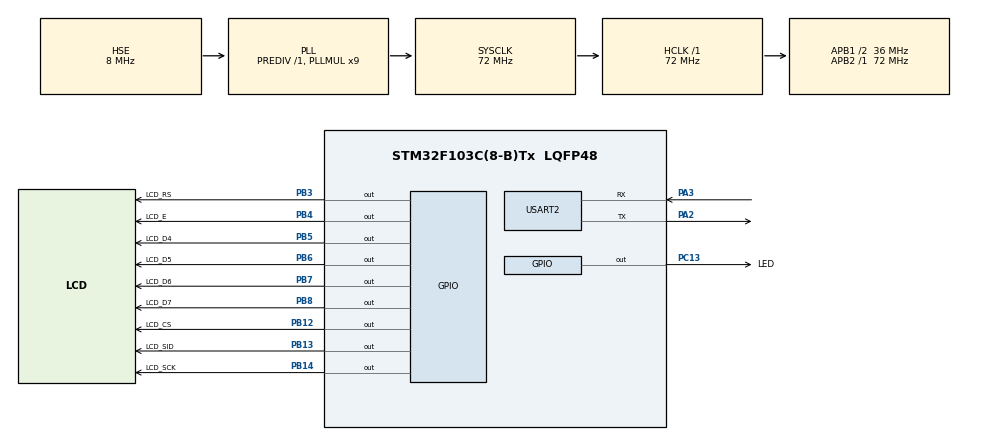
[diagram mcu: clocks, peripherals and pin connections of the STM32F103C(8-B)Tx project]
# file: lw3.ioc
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Dma.Request0=USART2_TX
Dma.Request1=USART2_RX
Dma.USART2_RX.1.Direction=DMA_PERIPH_TO_MEMORY
Dma.USART2_RX.1.Instance=DMA1_Channel6
Dma.USART2_RX.1.MemDataAlignment=DMA_MDATAALIGN_BYTE
Dma.USART2_RX.1.MemInc=DMA_MINC_ENABLE
Dma.USART2_RX.1.Mode=DMA_NORMAL
Dma.USART2_RX.1.PeriphDataAlignment=DMA_PDATAALIGN_BYTE
Dma.USART2_RX.1.PeriphInc=DMA_PINC_DISABLE
Dma.USART2_RX.1.Priority=DMA_PRIORITY_LOW
Dma.USART2_TX.0.Direction=DMA_MEMORY_TO_PERIPH
Dma.USART2_TX.0.Instance=DMA1_Channel7
Dma.USART2_TX.0.MemDataAlignment=DMA_MDATAALIGN_BYTE
Dma.USART2_TX.0.MemInc=DMA_MINC_ENABLE
Dma.USART2_TX.0.Mode=DMA_NORMAL
Dma.USART2_TX.0.PeriphDataAlignment=DMA_PDATAALIGN_BYTE
Dma.USART2_TX.0.PeriphInc=DMA_PINC_DISABLE
Dma.USART2_TX.0.Priority=DMA_PRIORITY_LOW
Mcu.Family=STM32F1
Mcu.Name=STM32F103C(8-B)Tx
Mcu.Package=LQFP48
NVIC.DMA1_Channel6_IRQn=true\:0\:0\:false\:false\:true\:false\:true\:true
NVIC.DMA1_Channel7_IRQn=true\:0\:0\:false\:false\:true\:false\:true\:true
NVIC.PriorityGroup=NVIC_PRIORITYGROUP_4
NVIC.USART2_IRQn=true\:0\:0\:false\:false\:true\:true\:true\:true
PA13.Mode=Serial_Wire
PA13.Signal=SYS_JTMS-SWDIO
PA14.Mode=Serial_Wire
PA14.Signal=SYS_JTCK-SWCLK
PA2.Mode=Asynchronous
PA2.Signal=USART2_TX
PA3.Mode=Asynchronous
PA3.Signal=USART2_RX
PB12.GPIO_Label=LCD_CS
PB12.Signal=GPIO_Output
PB13.GPIO_Label=LCD_SID
PB13.Signal=GPIO_Output
PB14.GPIO_Label=LCD_SCK
PB14.Signal=GPIO_Output
PB3.GPIO_Label=LCD_RS
PB3.Signal=GPIO_Output
PB4.GPIO_Label=LCD_E
PB4.Signal=GPIO_Output
PB5.GPIO_Label=LCD_D4
PB5.Signal=GPIO_Output
PB6.GPIO_Label=LCD_D5
PB6.Signal=GPIO_Output
PB7.GPIO_Label=LCD_D6
PB7.Signal=GPIO_Output
PB8.GPIO_Label=LCD_D7
PB8.Signal=GPIO_Output
PC13-TAMPER-RTC.GPIO_Label=LED
PC13-TAMPER-RTC.Signal=GPIO_Output
PD0-OSC_IN.Mode=HSE-External-Oscillator
PD0-OSC_IN.Signal=RCC_OSC_IN
PD1-OSC_OUT.Mode=HSE-External-Oscillator
PD1-OSC_OUT.Signal=RCC_OSC_OUT
ProjectManager.HeapSize=0x200
ProjectManager.StackSize=0x400
ProjectManager.TargetToolchain=Makefile
RCC.AHBFreq_Value=72000000
RCC.APB1CLKDivider=RCC_HCLK_DIV2
RCC.APB1Freq_Value=36000000
RCC.APB1TimFreq_Value=72000000
RCC.APB2Freq_Value=72000000
RCC.APB2TimFreq_Value=72000000
RCC.HCLKFreq_Value=72000000
RCC.PLLMUL=RCC_PLL_MUL9
RCC.PLLSourceVirtual=RCC_PLLSOURCE_HSE
RCC.SYSCLKFreq_VALUE=72000000
RCC.SYSCLKSource=RCC_SYSCLKSOURCE_PLLCLK
RCC.USBFreq_Value=72000000
USART2.VirtualMode=VM_ASYNC
board=custom

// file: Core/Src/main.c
/* USER CODE BEGIN Header */
/**
  ******************************************************************************
  * @file           : main.c
  * @brief          : Main program body
  ******************************************************************************
  * @attention
  *
  * Copyright (c) 2026 STMicroelectronics.
  * All rights reserved.
  *
  * This software is licensed under terms that can be found in the LICENSE file
  * in the root directory of this software component.
  * If no LICENSE file comes with this software, it is provided AS-IS.
  *
  ******************************************************************************
  */
/* USER CODE END Header */
#include "main.h"

/* USER CODE BEGIN Includes */
// !!!
#include "lcdST7920.h"     //#include "lcd.h"
/* USER CODE END Includes */

UART_HandleTypeDef huart2;
DMA_HandleTypeDef hdma_usart2_tx;
DMA_HandleTypeDef hdma_usart2_rx;

/* USER CODE BEGIN PV */
// !!!
uint8_t trans[] = "UART Transmit from STM32\n";
char received[9] = {0};
const int received_size = sizeof(received)/sizeof(char)-1;
/* USER CODE END PV */

void SystemClock_Config(void);
static void MX_GPIO_Init(void);
static void MX_DMA_Init(void);
static void MX_USART2_UART_Init(void);

int main(void)
{

  /* MCU Configuration--------------------------------------------------------*/

  /* Reset of all peripherals, Initializes the Flash interface and the Systick. */
  HAL_Init();

  /* Configure the system clock */
  SystemClock_Config();

  MX_GPIO_Init();
  MX_DMA_Init();
  MX_USART2_UART_Init();

  /* Infinite loop */
  /* USER CODE BEGIN WHILE */
  // !!!
  LCD_Init();
  LCD_Clear();
  LCD_SetPos(0, 0);
  LCD_String("Received: len=");
  LCD_Char(received_size + '0');
  HAL_UART_Receive_DMA(&huart2, (uint8_t*)received, received_size);
  while (1)
  {
    HAL_GPIO_TogglePin(LED_GPIO_Port, LED_Pin);
    HAL_UART_Transmit_DMA(&huart2, trans, sizeof(trans)-1);
    HAL_Delay(500);
    if(hdma_usart2_rx.State == HAL_DMA_STATE_READY) //if(huart2.RxXferCount == 0)
    {
      LCD_SetPos(0, 1);
      LCD_String(received);
      HAL_UART_Receive_DMA(&huart2, (uint8_t*)received, received_size); // Перезапуск прийом
      //hdma_usart2_rx.State = HAL_DMA_STATE_BUSY;// Скидання стану DMA для прийому, не обов'язково
    }
  }
  /* USER CODE END 3 */
}

void SystemClock_Config(void)
{
  RCC_OscInitTypeDef RCC_OscInitStruct = {0};
  RCC_ClkInitTypeDef RCC_ClkInitStruct = {0};

  /** Initializes the RCC Oscillators according to the specified parameters
  * in the RCC_OscInitTypeDef structure.
  */
  RCC_OscInitStruct.OscillatorType = RCC_OSCILLATORTYPE_HSE;
  RCC_OscInitStruct.HSEState = RCC_HSE_ON;
  RCC_OscInitStruct.HSEPredivValue = RCC_HSE_PREDIV_DIV1;
  RCC_OscInitStruct.HSIState = RCC_HSI_ON;
  RCC_OscInitStruct.PLL.PLLState = RCC_PLL_ON;
  RCC_OscInitStruct.PLL.PLLSource = RCC_PLLSOURCE_HSE;
  RCC_OscInitStruct.PLL.PLLMUL = RCC_PLL_MUL9;
  if (HAL_RCC_OscConfig(&RCC_OscInitStruct) != HAL_OK)
  {
    Error_Handler();
  }

  /** Initializes the CPU, AHB and APB buses clocks
  */
  RCC_ClkInitStruct.ClockType = RCC_CLOCKTYPE_HCLK|RCC_CLOCKTYPE_SYSCLK
                              |RCC_CLOCKTYPE_PCLK1|RCC_CLOCKTYPE_PCLK2;
  RCC_ClkInitStruct.SYSCLKSource = RCC_SYSCLKSOURCE_PLLCLK;
  RCC_ClkInitStruct.AHBCLKDivider = RCC_SYSCLK_DIV1;
  RCC_ClkInitStruct.APB1CLKDivider = RCC_HCLK_DIV2;
  RCC_ClkInitStruct.APB2CLKDivider = RCC_HCLK_DIV1;

  if (HAL_RCC_ClockConfig(&RCC_ClkInitStruct, FLASH_LATENCY_2) != HAL_OK)
  {
    Error_Handler();
  }
}

static void MX_USART2_UART_Init(void)
{

  huart2.Instance = USART2;
  huart2.Init.BaudRate = 115200;
  huart2.Init.WordLength = UART_WORDLENGTH_8B;
  huart2.Init.StopBits = UART_STOPBITS_1;
  huart2.Init.Parity = UART_PARITY_NONE;
  huart2.Init.Mode = UART_MODE_TX_RX;
  huart2.Init.HwFlowCtl = UART_HWCONTROL_NONE;
  huart2.Init.OverSampling = UART_OVERSAMPLING_16;
  if (HAL_UART_Init(&huart2) != HAL_OK)
  {
    Error_Handler();
  }

}

static void MX_DMA_Init(void)
{

  /* DMA controller clock enable */
  __HAL_RCC_DMA1_CLK_ENABLE();

  /* DMA interrupt init */
  /* DMA1_Channel6_IRQn interrupt configuration */
  HAL_NVIC_SetPriority(DMA1_Channel6_IRQn, 0, 0);
  HAL_NVIC_EnableIRQ(DMA1_Channel6_IRQn);
  /* DMA1_Channel7_IRQn interrupt configuration */
  HAL_NVIC_SetPriority(DMA1_Channel7_IRQn, 0, 0);
  HAL_NVIC_EnableIRQ(DMA1_Channel7_IRQn);

}

static void MX_GPIO_Init(void)
{
  GPIO_InitTypeDef GPIO_InitStruct = {0};

  /* GPIO Ports Clock Enable */
  __HAL_RCC_GPIOC_CLK_ENABLE();
  __HAL_RCC_GPIOD_CLK_ENABLE();
  __HAL_RCC_GPIOA_CLK_ENABLE();
  __HAL_RCC_GPIOB_CLK_ENABLE();

  /*Configure GPIO pin Output Level */
  HAL_GPIO_WritePin(LED_GPIO_Port, LED_Pin, GPIO_PIN_RESET);

  /*Configure GPIO pin Output Level */
  HAL_GPIO_WritePin(GPIOB, LCD_CS_Pin|LCD_SID_Pin|LCD_SCK_Pin|LCD_RS_Pin
                          |LCD_E_Pin|LCD_D4_Pin|LCD_D5_Pin|LCD_D6_Pin
                          |LCD_D7_Pin, GPIO_PIN_RESET);

  /*Configure GPIO pin : LED_Pin */
  GPIO_InitStruct.Pin = LED_Pin;
  GPIO_InitStruct.Mode = GPIO_MODE_OUTPUT_PP;
  GPIO_InitStruct.Pull = GPIO_NOPULL;
  GPIO_InitStruct.Speed = GPIO_SPEED_FREQ_LOW;
  HAL_GPIO_Init(LED_GPIO_Port, &GPIO_InitStruct);

  /*Configure GPIO pins : LCD_CS_Pin LCD_SID_Pin LCD_SCK_Pin LCD_RS_Pin
                           LCD_E_Pin LCD_D4_Pin LCD_D5_Pin LCD_D6_Pin
                           LCD_D7_Pin */
  GPIO_InitStruct.Pin = LCD_CS_Pin|LCD_SID_Pin|LCD_SCK_Pin|LCD_RS_Pin
                          |LCD_E_Pin|LCD_D4_Pin|LCD_D5_Pin|LCD_D6_Pin
                          |LCD_D7_Pin;
  GPIO_InitStruct.Mode = GPIO_MODE_OUTPUT_PP;
  GPIO_InitStruct.Pull = GPIO_NOPULL;
  GPIO_InitStruct.Speed = GPIO_SPEED_FREQ_LOW;
  HAL_GPIO_Init(GPIOB, &GPIO_InitStruct);

}

void Error_Handler(void)
{
  __disable_irq();
  while (1)
  {
  }
}
